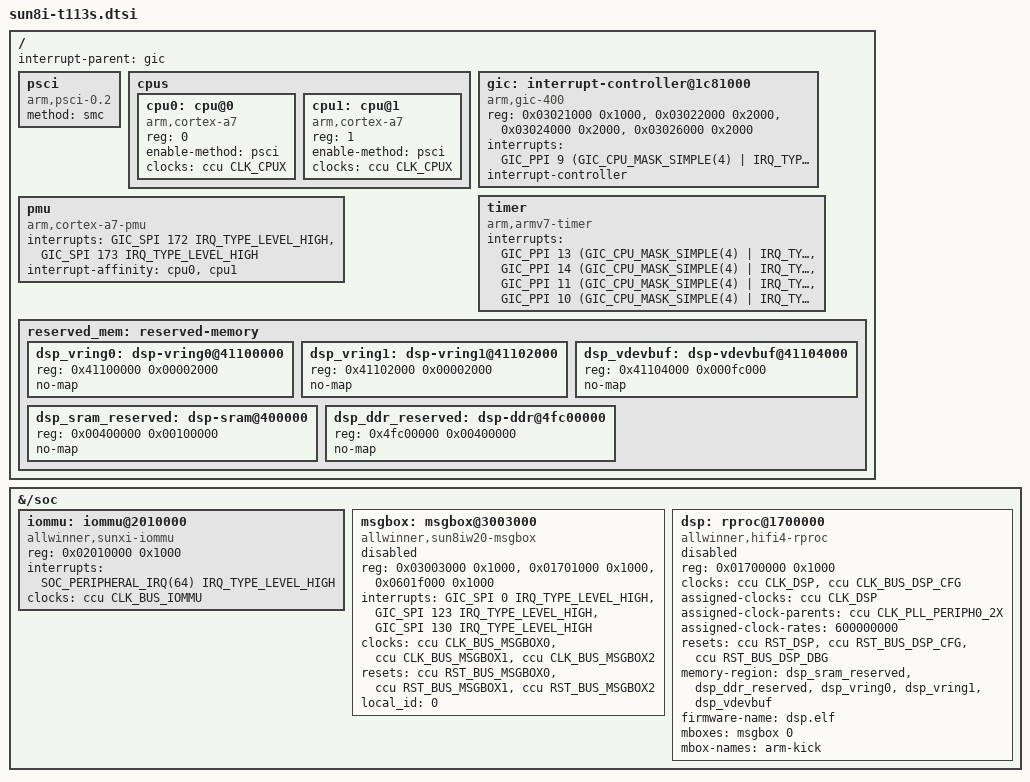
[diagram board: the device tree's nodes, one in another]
// SPDX-License-Identifier: (GPL-2.0+ OR MIT)
// Copyright (C) 2022 Arm Ltd.

#define SOC_PERIPHERAL_IRQ(nr) GIC_SPI nr

#include <dt-bindings/interrupt-controller/arm-gic.h>
#include <riscv/allwinner/sunxi-d1s-t113.dtsi>
#include <riscv/allwinner/sunxi-d1-t113.dtsi>

/ {
	interrupt-parent = <&gic>;

	psci {
		compatible = "arm,psci-0.2";
		method = "smc";
	};

	cpus {
		#address-cells = <1>;
		#size-cells = <0>;

		cpu0: cpu@0 {
			compatible = "arm,cortex-a7";
			device_type = "cpu";
			reg = <0>;
			enable-method = "psci";
			clocks = <&ccu CLK_CPUX>;
			clock-names = "cpu";
		};

		cpu1: cpu@1 {
			compatible = "arm,cortex-a7";
			device_type = "cpu";
			reg = <1>;
			enable-method = "psci";
			clocks = <&ccu CLK_CPUX>;
			clock-names = "cpu";
		};
	};

	gic: interrupt-controller@1c81000 {
		compatible = "arm,gic-400";
		reg = <0x03021000 0x1000>,
		      <0x03022000 0x2000>,
		      <0x03024000 0x2000>,
		      <0x03026000 0x2000>;
		interrupts = <GIC_PPI 9 (GIC_CPU_MASK_SIMPLE(4) | IRQ_TYPE_LEVEL_HIGH)>;
		interrupt-controller;
		#interrupt-cells = <3>;
	};

	timer {
		compatible = "arm,armv7-timer";
		interrupts = <GIC_PPI 13 (GIC_CPU_MASK_SIMPLE(4) | IRQ_TYPE_LEVEL_LOW)>,
			     <GIC_PPI 14 (GIC_CPU_MASK_SIMPLE(4) | IRQ_TYPE_LEVEL_LOW)>,
			     <GIC_PPI 11 (GIC_CPU_MASK_SIMPLE(4) | IRQ_TYPE_LEVEL_LOW)>,
			     <GIC_PPI 10 (GIC_CPU_MASK_SIMPLE(4) | IRQ_TYPE_LEVEL_LOW)>;
	};

	pmu {
		compatible = "arm,cortex-a7-pmu";
		interrupts = <GIC_SPI 172 IRQ_TYPE_LEVEL_HIGH>,
			     <GIC_SPI 173 IRQ_TYPE_LEVEL_HIGH>;
		interrupt-affinity = <&cpu0>, <&cpu1>;
	};

	
	reserved_mem:reserved-memory {
		#address-cells = <1>;
		#size-cells = <1>;
		ranges;

        dsp_vring0: dsp-vring0@41100000 {
            reg = <0x41100000 0x00002000>;
            no-map;
        };

        dsp_vring1: dsp-vring1@41102000 {
            reg = <0x41102000 0x00002000>;
            no-map;
        };

        dsp_vdevbuf: dsp-vdevbuf@41104000 {
            reg = <0x41104000 0x000fc000>;
            no-map;
        };

        dsp_sram_reserved: dsp-sram@400000 {
            /* DSP IRAM/TCM window */
            reg = <0x00400000 0x00100000>;
            no-map;
        };

        dsp_ddr_reserved: dsp-ddr@4fc00000 {
            reg = <0x4fc00000 0x00400000>;
            no-map;
        };
	};
};

&{/soc} {
	iommu: iommu@2010000 {
		compatible = "allwinner,sunxi-iommu";
		reg = <0x02010000 0x1000>;
		interrupts = <SOC_PERIPHERAL_IRQ(64) IRQ_TYPE_LEVEL_HIGH>;
		clocks = <&ccu CLK_BUS_IOMMU>;
		clock-names = "iommu";
		#iommu-cells = <2>;
		status = "okay";
	};

	msgbox: msgbox@3003000 {
		compatible = "allwinner,sun8iw20-msgbox";
		#mbox-cells = <1>;
		reg = <0x03003000 0x1000>,
		      <0x01701000 0x1000>,
		      <0x0601f000 0x1000>;
		interrupts = <GIC_SPI 0 IRQ_TYPE_LEVEL_HIGH>,
			    <GIC_SPI 123 IRQ_TYPE_LEVEL_HIGH>,
			    <GIC_SPI 130 IRQ_TYPE_LEVEL_HIGH>;
		clocks = <&ccu CLK_BUS_MSGBOX0>,<&ccu CLK_BUS_MSGBOX1>,
			 <&ccu CLK_BUS_MSGBOX2>;
		clock-names = "msgbox0","msgbox1",
			      "msgbox2";
		resets = <&ccu RST_BUS_MSGBOX0>,<&ccu RST_BUS_MSGBOX1>,
			 <&ccu RST_BUS_MSGBOX2>;
		reset-names = "rst0","rst1",
			      "rst2";
		local_id = <0>;
		status = "disabled";
	};

	dsp: rproc@1700000 {
        compatible = "allwinner,hifi4-rproc";
        reg = <0x01700000 0x1000>;
        reg-names = "dsp-cfg";

        clocks = <&ccu CLK_DSP>,
                <&ccu CLK_BUS_DSP_CFG>;
        clock-names = "core", "bus";

        assigned-clocks = <&ccu CLK_DSP>;
        assigned-clock-parents = <&ccu CLK_PLL_PERIPH0_2X>;
        assigned-clock-rates = <600000000>;

        resets = <&ccu RST_DSP>,
                <&ccu RST_BUS_DSP_CFG>,
                <&ccu RST_BUS_DSP_DBG>;
        reset-names = "core", "cfg", "dbg";

        memory-region = <&dsp_sram_reserved &dsp_ddr_reserved &dsp_vring0 &dsp_vring1 &dsp_vdevbuf>;
        firmware-name = "dsp.elf";
        mboxes = <&msgbox 0>;
        mbox-names = "arm-kick";
        status = "disabled";
    };
};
